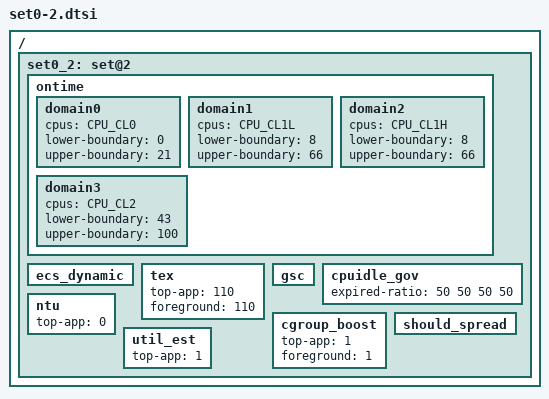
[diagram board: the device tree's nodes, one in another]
/ {
	/* normal mode - app boost */
	set0_2: set@2 {
		/* Ontime Migration */
		ontime {
			domain0 {
				cpus = CPU_CL0;
				lower-boundary = <0>;
				upper-boundary = <21>;
			};
			domain1 {
				cpus = CPU_CL1L;
				lower-boundary = <8>;
				upper-boundary = <66>;
			};
			domain2 {
				cpus = CPU_CL1H;
				lower-boundary = <8>;
				upper-boundary = <66>;
			};
			domain3 {
				cpus = CPU_CL2;
				lower-boundary = <43>;
				upper-boundary = <100>;
			};
		};

		ecs_dynamic { };

		tex {
			top-app = <110>;
			foreground = <110>;
		};

		gsc { };

		cpuidle_gov {
			expired-ratio = <50 50 50 50>;
		};

		ntu {
			top-app			= <0>;
		};

		cgroup_boost {
			top-app = <1>;
			foreground = <1>;
		};

		should_spread { };

		util_est {
			top-app	= <1>;
		};
	};
};
